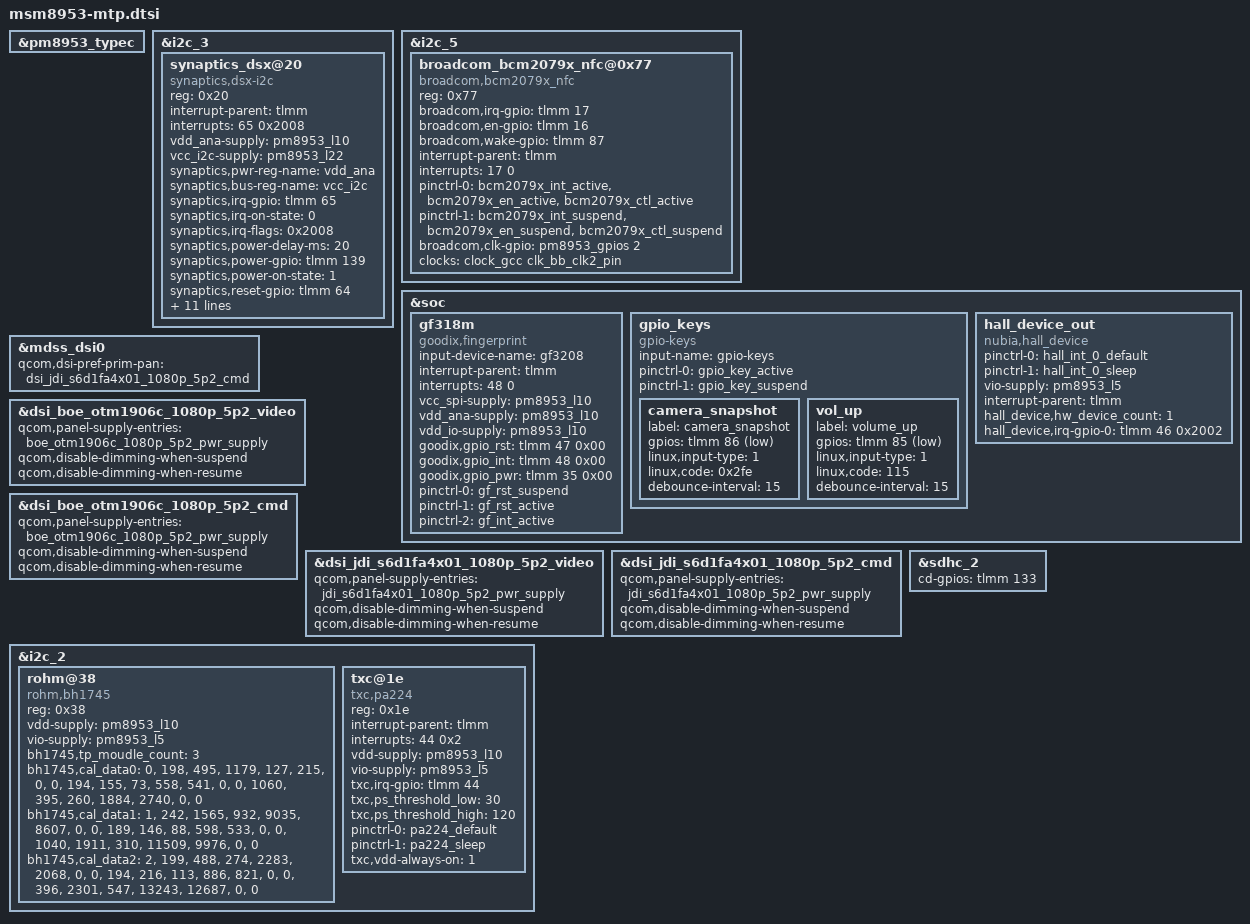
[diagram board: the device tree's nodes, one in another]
/*
 * Copyright (c) 2015-2016, The Linux Foundation. All rights reserved.
 *
 * This program is free software; you can redistribute it and/or modify
 * it under the terms of the GNU General Public License version 2 and
 * only version 2 as published by the Free Software Foundation.
 *
 * This program is distributed in the hope that it will be useful,
 * but WITHOUT ANY WARRANTY; without even the implied warranty of
 * MERCHANTABILITY or FITNESS FOR A PARTICULAR PURPOSE.  See the
 * GNU General Public License for more details.
 */

&pm8953_typec {
	//ssmux conflicting with nubia synaptics touchscreen
	/delete-property/ qcom,ssmux-gpio;
	/delete-property/ pinctrl-names;
	/delete-property/ pinctrl-0;
};

&i2c_3 {
	synaptics_dsx@20 {
		compatible = "synaptics,dsx-i2c";
		reg = <0x20>;
		interrupt-parent = <&tlmm>;
		interrupts = <65 0x2008>;
		vdd_ana-supply = <&pm8953_l10>;
		vcc_i2c-supply = <&pm8953_l22>;
		synaptics,pwr-reg-name = "vdd_ana";
		synaptics,bus-reg-name = "vcc_i2c";
		synaptics,irq-gpio = <&tlmm 65 0x2008>;
		synaptics,irq-on-state = <0>;
		synaptics,irq-flags = <0x2008>; /* IRQF_ONESHOT | IRQF_TRIGGER_LOW */
		synaptics,power-delay-ms = <20>;
		synaptics,power-gpio = <&tlmm 139 0x0>;
		synaptics,power-on-state = <1>;
		synaptics,reset-gpio = <&tlmm 64 0x0>;
		synaptics,reset-on-state = <0>;
		synaptics,reset-active-ms = <20>;
		synaptics,reset-delay-ms = <20>;
		synaptics,lcd-reset-gpio = <&tlmm 61 0x0>;
		synaptics,cap-button-codes = <158 139 172>;
		pinctrl-names = "synaptics_pin_active", "synaptics_pin_suspend";
		pinctrl-0 = <&synaptics_int_active &synaptics_reset_active &synaptics_power_active>;
		pinctrl-1 = <&synaptics_int_suspend &synaptics_reset_suspend &synaptics_power_suspend>;
	};
};

&i2c_5 { /* BLSP2 QUP1 (NFC) */
		/delete-node/ nq@28;
		broadcom_bcm2079x_nfc@0x77 {
			compatible = "broadcom,bcm2079x_nfc";
			reg = <0x77>;
			broadcom,irq-gpio = <&tlmm 17 0x00>;
			broadcom,en-gpio = <&tlmm 16 0x00>;
			broadcom,wake-gpio = <&tlmm 87 0x00>;
			interrupt-parent = <&tlmm>;
			interrupts = <17 0>;
			interrupt-names = "BRCM_NFC_INT";
			pinctrl-names = "bcm2079x_pin_active","bcm2079x_pin_suspend";
			pinctrl-0 = <&bcm2079x_int_active &bcm2079x_en_active &bcm2079x_ctl_active>;
			pinctrl-1 = <&bcm2079x_int_suspend &bcm2079x_en_suspend &bcm2079x_ctl_suspend>;
			broadcom,clk-gpio = <&pm8953_gpios 2 0x00>;
			clocks = <&clock_gcc clk_bb_clk2_pin>;
			clock-names = "ref_clk";
		};
};

&soc {
	/* used for fingerprint device as platform device added by nubia start*/
	gf318m {
		status = "ok";
		compatible = "goodix,fingerprint";
/*goodix origin start*/
//		spi-max-frequency = <4800000>;
//		reg = <0>;
		input-device-name = "gf3208";
		interrupt-parent = <&tlmm>;
		interrupts = <48 0>;
//		spi-qup-id = <11>;
		vcc_spi-supply = <&pm8953_l10>;
		vdd_ana-supply = <&pm8953_l10>;
		vdd_io-supply = <&pm8953_l10>;
		goodix,gpio_rst = <&tlmm 47 0x00>;
		goodix,gpio_int = <&tlmm 48 0x00>;
		goodix,gpio_pwr = <&tlmm 35 0x00>;
		pinctrl-names = "goodixfp_reset_reset", "goodixfp_reset_active", "goodixfp_irq_active";
		pinctrl-0 = <&gf_rst_suspend>;
		pinctrl-1 = <&gf_rst_active>;
		pinctrl-2 = <&gf_int_active>;
/*		clock-names = "iface_clk", "core_clk";
		clocks = <&clock_gcc clk_gcc_blsp2_ahb_clk>,
			<&clock_gcc clk_gcc_blsp2_qup5_spi_apps_clk>;
		clocks = <&clock_gcc clk_gcc_blsp2_ahb_clk>,
			<&clock_gcc clk_gcc_blsp2_qup3_spi_apps_clk>;
*/
/*goodix origin end*/
	};
	/* used for fingerprint device as platform device added by nubia end*/

	gpio_keys {
		compatible = "gpio-keys";
		input-name = "gpio-keys";
		pinctrl-names = "tlmm_gpio_key_active","tlmm_gpio_key_suspend";
		pinctrl-0 = <&gpio_key_active>;
		pinctrl-1 = <&gpio_key_suspend>;

		/delete-node/ camera_focus;
		camera_snapshot {
			label = "camera_snapshot";
			gpios = <&tlmm 86 0x1>;
			linux,input-type = <1>;
			linux,code = <0x2fe>;
			debounce-interval = <15>;
		};

		vol_up {
			label = "volume_up";
			gpios = <&tlmm 85 0x1>;
			linux,input-type = <1>;
			linux,code = <115>;
			debounce-interval = <15>;
		};
	};

	hall_device_out {
		compatible = "nubia,hall_device";
		status = "okay";
		pinctrl-names = "hall_default","hall_sleep";
		pinctrl-0 = <&hall_int_0_default >;
		pinctrl-1 = <&hall_int_0_sleep >;
		vio-supply = <&pm8953_l5>;
		interrupt-parent = <&tlmm>;
		hall_device,hw_device_count = <1>;
		hall_device,irq-gpio-0 = <&tlmm 46 0x2002>;
	};
};


&mdss_dsi0 {
	qcom,dsi-pref-prim-pan = <&dsi_jdi_s6d1fa4x01_1080p_5p2_cmd>;
	/delete-property/ qcom,platform-bklight-en-gpio;
};

//nubia for boe lcd
&dsi_boe_otm1906c_1080p_5p2_video {
	qcom,panel-supply-entries = <&boe_otm1906c_1080p_5p2_pwr_supply>;
	qcom,disable-dimming-when-suspend;
	qcom,disable-dimming-when-resume;
};

&dsi_boe_otm1906c_1080p_5p2_cmd {
	qcom,panel-supply-entries = <&boe_otm1906c_1080p_5p2_pwr_supply>;
	qcom,disable-dimming-when-suspend;
	qcom,disable-dimming-when-resume;
};

//nubia for jdi lcd
&dsi_jdi_s6d1fa4x01_1080p_5p2_video {
	qcom,panel-supply-entries = <&jdi_s6d1fa4x01_1080p_5p2_pwr_supply>;
	qcom,disable-dimming-when-suspend;
	qcom,disable-dimming-when-resume;
};

&dsi_jdi_s6d1fa4x01_1080p_5p2_cmd {
	qcom,panel-supply-entries = <&jdi_s6d1fa4x01_1080p_5p2_pwr_supply>;
	qcom,disable-dimming-when-suspend;
	qcom,disable-dimming-when-resume;
};


&sdhc_2 {
	cd-gpios = <&tlmm 133 0x0>;
};

&i2c_2{
	rohm@38 {
		compatible = "rohm,bh1745";
		reg = <0x38>;
		vdd-supply = <&pm8953_l10>;
	  vio-supply = <&pm8953_l5>;
		bh1745,tp_moudle_count = <3>;
		/*[module_id] [golden judge] r[0] r[1] g[0] g[1] b[0] b[1]*/
		bh1745,cal_data0 = "0","198","495","1179","127","215","0","0",
		/*[white judge] r[0] r[1] g[0] g[1] b[0] b[1]*/
		"194","155","73","558","541","0","0",
		/*[balck judge] r[0] r[1] g[0] g[1] b[0] b[1]*/
		"1060","395","260","1884","2740","0","0";
		/*[module_id] [golden judge] r[0] r[1] g[0] g[1] b[0] b[1]*/
		bh1745,cal_data1 = "1","242","1565","932","9035","8607","0","0",
		/*[white judge] r[0] r[1] g[0] g[1] b[0] b[1]*/
		"189","146","88","598","533","0","0",
		/*[balck judge] r[0] r[1] g[0] g[1] b[0] b[1]*/
		"1040","1911","310","11509","9976","0","0";
		/*[module_id] [golden judge] r[0] r[1] g[0] g[1] b[0] b[1]*/
		bh1745,cal_data2 = "2","199","488","274","2283","2068","0","0",
		/*[white judge] r[0] r[1] g[0] g[1] b[0] b[1]*/
		"194","216","113","886","821","0","0",
		/*[balck judge] r[0] r[1] g[0] g[1] b[0] b[1]*/
		"396","2301","547","13243","12687","0","0";
	};


	txc@1e {
		compatible = "txc,pa224";
		reg = <0x1e>;
		interrupt-parent = <&tlmm>;
		interrupts = <44 0x2>;
		vdd-supply = <&pm8953_l10>;
		vio-supply = <&pm8953_l5>;
		txc,irq-gpio = <&tlmm 44 0x2002>;
		txc,ps_threshold_low = <30>;
		txc,ps_threshold_high = <120>;
		pinctrl-names = "pa224_default","pa224_sleep";
		pinctrl-0 = <&pa224_default>;
		pinctrl-1 =<&pa224_sleep>;
		txc,vdd-always-on = <1>;
	};

};
